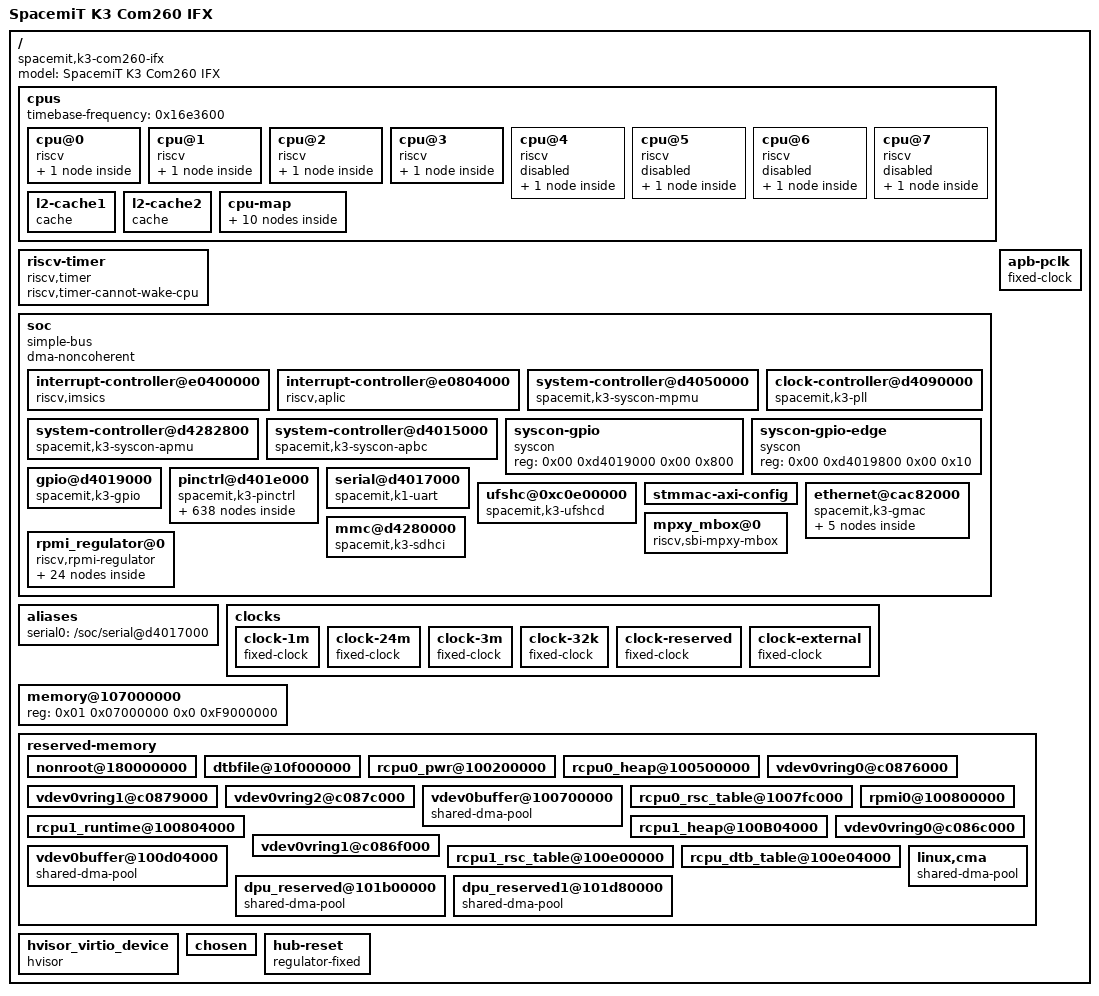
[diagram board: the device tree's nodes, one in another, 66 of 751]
/dts-v1/;

/ {
	#address-cells = <0x02>;
	#size-cells = <0x02>;
	model = "SpacemiT K3 Com260 IFX";
	compatible = "spacemit,k3-com260-ifx";

	cpus {
		#address-cells = <0x01>;
		#size-cells = <0x00>;
		timebase-frequency = <0x16e3600>;

		cpu@0 {
			device_type = "cpu";
			reg = <0x00>;
			model = "Spacemit(R) X100";
			status = "okay";
			compatible = "riscv";
			riscv,isa = "rv64imafdcv";
			riscv,isa-base = "rv64i";
			riscv,isa-extensions = "i\0m\0a\0f\0d\0c\0v\0smaia\0smstateen\0ssaia\0sscofpmf\0sstc\0svpbmt\0svinval\0svnapot\0zawrs\0zba\0zbb\0zbc\0zbs\0zcb\0zca\0zcmop\0zfa\0zfh\0zfhmin\0zkt\0zicbom\0zicbop\0zicboz\0zicntr\0zicond\0zicsr\0zifencei\0zihintpause\0zihintntl\0zihpm\0zimop\0zvbb\0zvbc\0zvfh\0zvfhmin\0zvkb\0zvkg\0zvkn\0zvknc\0zvkned\0zvkng\0zvknha\0zvknhb\0zvks\0zvksc\0zvksed\0zvksh\0zvksg\0zvkt\0zcd";
			riscv,cbom-block-size = <0x40>;
			riscv,cboz-block-size = <0x40>;
			riscv,cbop-block-size = <0x40>;
			i-cache-block-size = <0x40>;
			i-cache-size = <0x10000>;
			i-cache-sets = <0x100>;
			d-cache-block-size = <0x40>;
			d-cache-size = <0x10000>;
			d-cache-sets = <0x100>;
			next-level-cache = <0x01>;
			// cpu-idle-states = <0x02 0x03>;
			mmu-type = "riscv,sv39";
			#cooling-cells = <0x02>;
			clst-supply = <0x04>;
			clocks = <0x05 0x04 0x05 0x05>;
			clock-names = "cls0\0cls1";
			// operating-points-v2 = <0x06>;
			phandle = <0x0b>;

			interrupt-controller {
				#interrupt-cells = <0x01>;
				compatible = "riscv,cpu-intc";
				interrupt-controller;
				phandle = <0x69>;
			};
		};

		cpu@1 {
			device_type = "cpu";
			reg = <0x01>;
			model = "Spacemit(R) X100";
			status = "okay";
			compatible = "riscv";
			riscv,isa = "rv64imafdcv";
			riscv,isa-base = "rv64i";
			riscv,isa-extensions = "i\0m\0a\0f\0d\0c\0v\0smaia\0smstateen\0ssaia\0sscofpmf\0sstc\0svpbmt\0svinval\0svnapot\0zawrs\0zba\0zbb\0zbc\0zbs\0zcb\0zca\0zcmop\0zfa\0zfh\0zfhmin\0zkt\0zicbom\0zicbop\0zicboz\0zicntr\0zicond\0zicsr\0zifencei\0zihintpause\0zihintntl\0zihpm\0zimop\0zvbb\0zvbc\0zvfh\0zvfhmin\0zvkb\0zvkg\0zvkn\0zvknc\0zvkned\0zvkng\0zvknha\0zvknhb\0zvks\0zvksc\0zvksed\0zvksh\0zvksg\0zvkt\0zcd";
			riscv,cbom-block-size = <0x40>;
			riscv,cboz-block-size = <0x40>;
			riscv,cbop-block-size = <0x40>;
			i-cache-block-size = <0x40>;
			i-cache-size = <0x10000>;
			i-cache-sets = <0x100>;
			d-cache-block-size = <0x40>;
			d-cache-size = <0x10000>;
			d-cache-sets = <0x100>;
			next-level-cache = <0x01>;
			// cpu-idle-states = <0x02 0x03>;
			mmu-type = "riscv,sv39";
			#cooling-cells = <0x02>;
			clst-supply = <0x04>;
			clocks = <0x05 0x04 0x05 0x05>;
			clock-names = "cls0\0cls1";
			// operating-points-v2 = <0x06>;
			phandle = <0x0c>;

			interrupt-controller {
				#interrupt-cells = <0x01>;
				compatible = "riscv,cpu-intc";
				interrupt-controller;
				phandle = <0x6a>;
			};
		};

		cpu@2 {
			device_type = "cpu";
			reg = <0x02>;
			model = "Spacemit(R) X100";
			status = "okay";
			compatible = "riscv";
			riscv,isa = "rv64imafdcv";
			riscv,isa-base = "rv64i";
			riscv,isa-extensions = "i\0m\0a\0f\0d\0c\0v\0smaia\0smstateen\0ssaia\0sscofpmf\0sstc\0svpbmt\0svinval\0svnapot\0zawrs\0zba\0zbb\0zbc\0zbs\0zcb\0zca\0zcmop\0zfa\0zfh\0zfhmin\0zkt\0zicbom\0zicbop\0zicboz\0zicntr\0zicond\0zicsr\0zifencei\0zihintpause\0zihintntl\0zihpm\0zimop\0zvbb\0zvbc\0zvfh\0zvfhmin\0zvkb\0zvkg\0zvkn\0zvknc\0zvkned\0zvkng\0zvknha\0zvknhb\0zvks\0zvksc\0zvksed\0zvksh\0zvksg\0zvkt\0zcd";
			riscv,cbom-block-size = <0x40>;
			riscv,cboz-block-size = <0x40>;
			riscv,cbop-block-size = <0x40>;
			i-cache-block-size = <0x40>;
			i-cache-size = <0x10000>;
			i-cache-sets = <0x100>;
			d-cache-block-size = <0x40>;
			d-cache-size = <0x10000>;
			d-cache-sets = <0x100>;
			next-level-cache = <0x01>;
			// cpu-idle-states = <0x02 0x03>;
			mmu-type = "riscv,sv39";
			#cooling-cells = <0x02>;
			clst-supply = <0x04>;
			clocks = <0x05 0x04 0x05 0x05>;
			clock-names = "cls0\0cls1";
			// operating-points-v2 = <0x06>;
			phandle = <0x0d>;

			interrupt-controller {
				#interrupt-cells = <0x01>;
				compatible = "riscv,cpu-intc";
				interrupt-controller;
				phandle = <0x6b>;
			};
		};

		cpu@3 {
			device_type = "cpu";
			reg = <0x03>;
			model = "Spacemit(R) X100";
			status = "okay";
			compatible = "riscv";
			riscv,isa = "rv64imafdcv";
			riscv,isa-base = "rv64i";
			riscv,isa-extensions = "i\0m\0a\0f\0d\0c\0v\0smaia\0smstateen\0ssaia\0sscofpmf\0sstc\0svpbmt\0svinval\0svnapot\0zawrs\0zba\0zbb\0zbc\0zbs\0zcb\0zca\0zcmop\0zfa\0zfh\0zfhmin\0zkt\0zicbom\0zicbop\0zicboz\0zicntr\0zicond\0zicsr\0zifencei\0zihintpause\0zihintntl\0zihpm\0zimop\0zvbb\0zvbc\0zvfh\0zvfhmin\0zvkb\0zvkg\0zvkn\0zvknc\0zvkned\0zvkng\0zvknha\0zvknhb\0zvks\0zvksc\0zvksed\0zvksh\0zvksg\0zvkt\0zcd";
			riscv,cbom-block-size = <0x40>;
			riscv,cboz-block-size = <0x40>;
			riscv,cbop-block-size = <0x40>;
			i-cache-block-size = <0x40>;
			i-cache-size = <0x10000>;
			i-cache-sets = <0x100>;
			d-cache-block-size = <0x40>;
			d-cache-size = <0x10000>;
			d-cache-sets = <0x100>;
			next-level-cache = <0x01>;
			// cpu-idle-states = <0x02 0x03>;
			mmu-type = "riscv,sv39";
			#cooling-cells = <0x02>;
			clst-supply = <0x04>;
			clocks = <0x05 0x04 0x05 0x05>;
			clock-names = "cls0\0cls1";
			// operating-points-v2 = <0x06>;
			phandle = <0x0e>;

			interrupt-controller {
				#interrupt-cells = <0x01>;
				compatible = "riscv,cpu-intc";
				interrupt-controller;
				phandle = <0x6c>;
			};
		};

		cpu@4 {
			device_type = "cpu";
			reg = <0x04>;
			model = "Spacemit(R) X100";
			status = "disabled";
			compatible = "riscv";
			riscv,isa = "rv64imafdcv";
			riscv,isa-base = "rv64i";
			riscv,isa-extensions = "i\0m\0a\0f\0d\0c\0v\0smaia\0smstateen\0ssaia\0sscofpmf\0sstc\0svpbmt\0svinval\0svnapot\0zawrs\0zba\0zbb\0zbc\0zbs\0zcb\0zca\0zcmop\0zfa\0zfh\0zfhmin\0zkt\0zicbom\0zicbop\0zicboz\0zicntr\0zicond\0zicsr\0zifencei\0zihintpause\0zihintntl\0zihpm\0zimop\0zvbb\0zvbc\0zvfh\0zvfhmin\0zvkb\0zvkg\0zvkn\0zvknc\0zvkned\0zvkng\0zvknha\0zvknhb\0zvks\0zvksc\0zvksed\0zvksh\0zvksg\0zvkt\0zcd";
			riscv,cbom-block-size = <0x40>;
			riscv,cboz-block-size = <0x40>;
			riscv,cbop-block-size = <0x40>;
			i-cache-block-size = <0x40>;
			i-cache-size = <0x10000>;
			i-cache-sets = <0x100>;
			d-cache-block-size = <0x40>;
			d-cache-size = <0x10000>;
			d-cache-sets = <0x100>;
			next-level-cache = <0x07>;
			// cpu-idle-states = <0x02 0x03>;
			mmu-type = "riscv,sv39";
			#cooling-cells = <0x02>;
			clst-supply = <0x04>;
			clocks = <0x05 0x04 0x05 0x05>;
			clock-names = "cls0\0cls1";
			// operating-points-v2 = <0x06>;
			phandle = <0x0f>;

			interrupt-controller {
				#interrupt-cells = <0x01>;
				compatible = "riscv,cpu-intc";
				interrupt-controller;
				phandle = <0x6d>;
			};
		};

		cpu@5 {
			device_type = "cpu";
			reg = <0x05>;
			model = "Spacemit(R) X100";
			status = "disabled";
			compatible = "riscv";
			riscv,isa = "rv64imafdcv";
			riscv,isa-base = "rv64i";
			riscv,isa-extensions = "i\0m\0a\0f\0d\0c\0v\0smaia\0smstateen\0ssaia\0sscofpmf\0sstc\0svpbmt\0svinval\0svnapot\0zawrs\0zba\0zbb\0zbc\0zbs\0zcb\0zca\0zcmop\0zfa\0zfh\0zfhmin\0zkt\0zicbom\0zicbop\0zicboz\0zicntr\0zicond\0zicsr\0zifencei\0zihintpause\0zihintntl\0zihpm\0zimop\0zvbb\0zvbc\0zvfh\0zvfhmin\0zvkb\0zvkg\0zvkn\0zvknc\0zvkned\0zvkng\0zvknha\0zvknhb\0zvks\0zvksc\0zvksed\0zvksh\0zvksg\0zvkt\0zcd";
			riscv,cbom-block-size = <0x40>;
			riscv,cboz-block-size = <0x40>;
			riscv,cbop-block-size = <0x40>;
			i-cache-block-size = <0x40>;
			i-cache-size = <0x10000>;
			i-cache-sets = <0x100>;
			d-cache-block-size = <0x40>;
			d-cache-size = <0x10000>;
			d-cache-sets = <0x100>;
			next-level-cache = <0x07>;
			// cpu-idle-states = <0x02 0x03>;
			mmu-type = "riscv,sv39";
			#cooling-cells = <0x02>;
			clst-supply = <0x04>;
			clocks = <0x05 0x04 0x05 0x05>;
			clock-names = "cls0\0cls1";
			// operating-points-v2 = <0x06>;
			phandle = <0x10>;

			interrupt-controller {
				#interrupt-cells = <0x01>;
				compatible = "riscv,cpu-intc";
				interrupt-controller;
				phandle = <0x6e>;
			};
		};

		cpu@6 {
			device_type = "cpu";
			reg = <0x06>;
			model = "Spacemit(R) X100";
			status = "disabled";
			compatible = "riscv";
			riscv,isa = "rv64imafdcv";
			riscv,isa-base = "rv64i";
			riscv,isa-extensions = "i\0m\0a\0f\0d\0c\0v\0smaia\0smstateen\0ssaia\0sscofpmf\0sstc\0svpbmt\0svinval\0svnapot\0zawrs\0zba\0zbb\0zbc\0zbs\0zcb\0zca\0zcmop\0zfa\0zfh\0zfhmin\0zkt\0zicbom\0zicbop\0zicboz\0zicntr\0zicond\0zicsr\0zifencei\0zihintpause\0zihintntl\0zihpm\0zimop\0zvbb\0zvbc\0zvfh\0zvfhmin\0zvkb\0zvkg\0zvkn\0zvknc\0zvkned\0zvkng\0zvknha\0zvknhb\0zvks\0zvksc\0zvksed\0zvksh\0zvksg\0zvkt\0zcd";
			riscv,cbom-block-size = <0x40>;
			riscv,cboz-block-size = <0x40>;
			riscv,cbop-block-size = <0x40>;
			i-cache-block-size = <0x40>;
			i-cache-size = <0x10000>;
			i-cache-sets = <0x100>;
			d-cache-block-size = <0x40>;
			d-cache-size = <0x10000>;
			d-cache-sets = <0x100>;
			next-level-cache = <0x07>;
			// cpu-idle-states = <0x02 0x03>;
			mmu-type = "riscv,sv39";
			#cooling-cells = <0x02>;
			clst-supply = <0x04>;
			clocks = <0x05 0x04 0x05 0x05>;
			clock-names = "cls0\0cls1";
			// operating-points-v2 = <0x06>;
			phandle = <0x11>;

			interrupt-controller {
				#interrupt-cells = <0x01>;
				compatible = "riscv,cpu-intc";
				interrupt-controller;
				phandle = <0x6f>;
			};
		};

		cpu@7 {
			device_type = "cpu";
			reg = <0x07>;
			model = "Spacemit(R) X100";
			status = "disabled";
			compatible = "riscv";
			riscv,isa = "rv64imafdcv";
			riscv,isa-base = "rv64i";
			riscv,isa-extensions = "i\0m\0a\0f\0d\0c\0v\0smaia\0smstateen\0ssaia\0sscofpmf\0sstc\0svpbmt\0svinval\0svnapot\0zawrs\0zba\0zbb\0zbc\0zbs\0zcb\0zca\0zcmop\0zfa\0zfh\0zfhmin\0zkt\0zicbom\0zicbop\0zicboz\0zicntr\0zicond\0zicsr\0zifencei\0zihintpause\0zihintntl\0zihpm\0zimop\0zvbb\0zvbc\0zvfh\0zvfhmin\0zvkb\0zvkg\0zvkn\0zvknc\0zvkned\0zvkng\0zvknha\0zvknhb\0zvks\0zvksc\0zvksed\0zvksh\0zvksg\0zvkt\0zcd";
			riscv,cbom-block-size = <0x40>;
			riscv,cboz-block-size = <0x40>;
			riscv,cbop-block-size = <0x40>;
			i-cache-block-size = <0x40>;
			i-cache-size = <0x10000>;
			i-cache-sets = <0x100>;
			d-cache-block-size = <0x40>;
			d-cache-size = <0x10000>;
			d-cache-sets = <0x100>;
			next-level-cache = <0x07>;
			// cpu-idle-states = <0x02 0x03>;
			mmu-type = "riscv,sv39";
			#cooling-cells = <0x02>;
			clst-supply = <0x04>;
			clocks = <0x05 0x04 0x05 0x05>;
			clock-names = "cls0\0cls1";
			// operating-points-v2 = <0x06>;
			phandle = <0x12>;

			interrupt-controller {
				#interrupt-cells = <0x01>;
				compatible = "riscv,cpu-intc";
				interrupt-controller;
				phandle = <0x70>;
			};
		};

		l2-cache1 {
			compatible = "cache";
			cache-block-size = <0x40>;
			cache-level = <0x02>;
			cache-size = <0x400000>;
			cache-sets = <0x1000>;
			cache-unified;
			phandle = <0x01>;
		};

		l2-cache2 {
			compatible = "cache";
			cache-block-size = <0x40>;
			cache-level = <0x02>;
			cache-size = <0x400000>;
			cache-sets = <0x1000>;
			cache-unified;
			phandle = <0x07>;
		};

		cpu-map {
			cluster0 {
				core0 {
					cpu = <0x0b>;
				};

				core1 {
					cpu = <0x0c>;
				};

				core2 {
					cpu = <0x0d>;
				};

				core3 {
					cpu = <0x0e>;
				};
			};

			cluster1 {

				core0 {
					cpu = <0x0f>;
				};

				core1 {
					cpu = <0x10>;
				};

				core2 {
					cpu = <0x11>;
				};

				core3 {
					cpu = <0x12>;
				};
			};
		};
	};

	riscv-timer {
		compatible = "riscv,timer";
		riscv,timer-cannot-wake-cpu;
	};

	soc {
		#address-cells = <0x02>;
		#size-cells = <0x02>;
		compatible = "simple-bus";
		dma-noncoherent;
		ranges;

		interrupt-controller@e0400000 {
			compatible = "riscv,imsics";
			interrupts-extended = <0x69 0x09 0x6a 0x09 0x6b 0x09 0x6c 0x09>;
			reg = <0x00 0xe0400000 0x00 0x4000>;
			interrupt-controller;
			#interrupt-cells = <0x00>;
			#msi-cells = <0x00>;
			msi-controller;
			riscv,num-ids = <0x1ff>;
			riscv,num-guest-ids = <0x1ff>;
			riscv,hart-index-bits = <0x03>;
			riscv,guest-index-bits = <0>;
			status = "okay";
			phandle = <0x79>;
		};

		interrupt-controller@e0804000 {
			compatible = "riscv,aplic";
			reg = <0x00 0xe0804000 0x00 0x4000>;
			msi-parent = <0x79>;
			#interrupt-cells = <0x02>;
			interrupt-controller;
			riscv,num-sources = <0x200>;
			status = "okay";
			phandle = <0x82>;
		};

		system-controller@d4050000 {
			compatible = "spacemit,k3-syscon-mpmu";
			reg = <0x00 0xd4050000 0x00 0x10000>;
			clocks = <0x7a 0x7b 0x7c 0x7d 0x7e 0x7f>;
			clock-names = "osc_32k\0vctcxo_1m\0vctcxo_3m\0vctcxo_24m\0reserved_clk\0external_clk";
			#clock-cells = <0x01>;
			#reset-cells = <0x01>;
			phandle = <0x80>;
		};

		clock-controller@d4090000 {
			compatible = "spacemit,k3-pll";
			reg = <0x00 0xd4090000 0x00 0x10000>;
			clocks = <0x7d>;
			spacemit,mpmu = <0x80>;
			#clock-cells = <0x01>;
			phandle = <0x1b>;
		};

		system-controller@d4282800 {
			compatible = "spacemit,k3-syscon-apmu";
			reg = <0x00 0xd4282800 0x00 0x400>;
			clocks = <0x7a 0x7b 0x7c 0x7d 0x7e 0x7f>;
			clock-names = "osc_32k\0vctcxo_1m\0vctcxo_3m\0vctcxo_24m\0reserved_clk\0external_clk";
			#clock-cells = <0x01>;
			#power-domain-cells = <0x01>;
			#reset-cells = <0x01>;
			phandle = <0x05>;
		};

		system-controller@d4015000 {
			compatible = "spacemit,k3-syscon-apbc";
			reg = <0x00 0xd4015000 0x00 0x1000>;
			clocks = <0x7a 0x7b 0x7c 0x7d 0x7e 0x7f>;
			clock-names = "osc_32k\0vctcxo_1m\0vctcxo_3m\0vctcxo_24m\0reserved_clk\0external_clk";
			#clock-cells = <0x01>;
			#reset-cells = <0x01>;
			phandle = <0x81>;
		};

		syscon-gpio {
			compatible = "syscon";
			reg = <0x00 0xd4019000 0x00 0x800>;
			phandle = <0x83>;
		};

		syscon-gpio-edge {
			compatible = "syscon";
			reg = <0x00 0xd4019800 0x00 0x10>;
			phandle = <0x84>;
		};

		gpio@d4019000 {
			compatible = "spacemit,k3-gpio";
			reg = <0x00 0xd4019000 0x00 0x100>;
			clocks = <0x81 0x14 0x81 0x15>;
			clock-names = "core\0bus";
			gpio-controller;
			#gpio-cells = <0x03>;
			interrupts = <0x3a 0x04>;
			interrupt-parent = <0x82>;
			interrupt-controller;
			#interrupt-cells = <0x03>;
			syscon-gpio-regs = <0x83>;
			syscon-gpio-edge = <0x84>;
			gpio-ranges = <0x85 0x00 0x00 0x00 0x20 0x85 0x01 0x00 0x20 0x20 0x85 0x02 0x00 0x40 0x20 0x85 0x03 0x00 0x60 0x20>;
			phandle = <0x8b>;
		};

		pinctrl@d401e000 {
			compatible = "spacemit,k3-pinctrl";
			reg = <0x00 0xd401e000 0x00 0x400 0x00 0xd401e800 0x00 0x34>;
			clocks = <0x81 0x67 0x81 0x68>;
			clock-names = "func\0bus";
			interrupt-controller;
			#interrupt-cells = <0x02>;
			interrupts = <0x3c 0x04>;
			interrupt-parent = <0x82>;
			spacemit,gpio-edge = <0x84>;
			spacemit,apbc = <0x81 0x50>;
			spacemit,apmu = <0x05>;
			phandle = <0x85>;

			uart0-0-cfg {
				phandle = <0x86>;

				uart0-0-pins {
					pinmux = <0x950002 0x960002>;
					bias-pull-up;
					drive-strength = <0x19>;
				};
			};

			uart0-1-cfg {

				uart0-0-pins {
					pinmux = <0x840002 0x850002>;
					bias-pull-up;
					drive-strength = <0x19>;
				};
			};

			uart0-2-cfg {

				uart0-0-pins {
					pinmux = <0x910005 0x920005>;
					bias-pull-up;
					drive-strength = <0x19>;
				};
			};

			uart0-3-cfg {

				uart0-0-pins {
					pinmux = <0x2a0002 0x2b0002>;
					bias-pull-up;
					drive-strength = <0x19>;
				};
			};

			uart0-4-cfg {

				uart0-0-pins {
					pinmux = <0x5d0003 0x5e0003>;
					bias-pull-up;
					drive-strength = <0x19>;
				};
			};

			uart1-0-cfg {

				uart1-0-pins {
					pinmux = <0x5f0002 0x600002 0x610002 0x620002>;
					bias-pull-up;
					drive-strength = <0x19>;
				};
			};

			uart1-1-cfg {

				uart1-0-pins {
					pinmux = <0x760001 0x770001 0x780001 0x790001>;
					bias-pull-up;
					drive-strength = <0x19>;
				};
			};

			uart2-0-cfg {

				uart2-0-pins {
					pinmux = <0x860002 0x870002 0x880002 0x890002>;
					bias-pull-up;
					drive-strength = <0x19>;
				};
			};

			uart2-1-cfg {

				uart2-0-pins {
					pinmux = <0x610001 0x620001>;
					bias-pull-up;
					drive-strength = <0x19>;
				};
			};

			uart3-0-cfg {

				uart3-0-pins {
					pinmux = <0x1a0002 0x1b0002 0x1c0002 0x1d0002>;
					bias-pull-up;
					drive-strength = <0x19>;
				};
			};

			uart3-1-cfg {

				uart3-0-pins {
					pinmux = <0x350002 0x360002 0x370002 0x380002>;
					bias-pull-up;
					drive-strength = <0x19>;
				};
			};

			uart4-0-cfg {

				uart4-0-pins {
					pinmux = <0x560003 0x570003 0x5a0003 0x5b0003>;
					bias-pull-up;
					drive-strength = <0x19>;
				};
			};

			uart4-1-cfg {

				uart4-0-pins {
					pinmux = <0x630003 0x640003 0x650003 0x660003>;
					bias-pull-up;
					drive-strength = <0x19>;
				};
			};

			uart5-0-cfg {

				uart5-0-pins {
					pinmux = <0x910004 0x920004>;
					bias-pull-up;
					drive-strength = <0x19>;
				};
			};

			uart5-1-cfg {

				uart5-0-pins {
					pinmux = <0x150002 0x160002 0x170002 0x180002>;
					bias-pull-up;
					drive-strength = <0x19>;
				};
			};

			uart5-2-cfg {

				uart5-0-pins {
					pinmux = <0x520004 0x530004>;
					bias-pull-up;
					drive-strength = <0x19>;
				};
			};

			uart6-0-cfg {

				uart6-0-pins {
					pinmux = <0x300002 0x310002 0x320002 0x330002>;
					bias-pull-up;
					drive-strength = <0x19>;
				};
			};

			uart6-1-cfg {

				uart6-0-pins {
					pinmux = <0x7a0003 0x7b0003>;
					bias-pull-up;
					drive-strength = <0x19>;
				};
			};

			uart7-0-cfg {

				uart7-0-pins {
					pinmux = <0xb0002 0xc0002 0xd0002 0xe0002>;
					bias-pull-up;
					drive-strength = <0x19>;
				};
			};

			uart7-1-cfg {

				uart7-0-pins {
					pinmux = <0x170005 0x180005 0x190005 0x1a0005>;
					bias-pull-up;
					drive-strength = <0x19>;
				};
			};

			uart8-0-cfg {

				uart8-0-pins {
					pinmux = <0xb0005 0xc0005>;
					bias-pull-up;
					drive-strength = <0x19>;
				};
			};

			uart8-1-cfg {

				uart8-0-pins {
					pinmux = <0x4c0003 0x4d0003 0x4e0003 0x4f0003>;
					bias-pull-up;
					drive-strength = <0x19>;
				};
			};

			uart9-0-cfg {

				uart9-0-pins {
					pinmux = <0x930004 0x940004>;
					bias-pull-up;
					drive-strength = <0x19>;
				};
			};

			uart9-1-cfg {

				uart9-0-pins {
					pinmux = <0x520003 0x530003 0x540003 0x550003>;
					bias-pull-up;
					drive-strength = <0x19>;
				};
			};

			uart10-0-cfg {

				uart10-0-pins {
					pinmux = <0x1f0002 0x200002 0x210002 0x220002>;
					bias-pull-up;
					drive-strength = <0x19>;
				};
			};

			uart10-1-cfg {

				uart10-0-pins {
					pinmux = <0x2c0002 0x2d0002 0x2e0002 0x2f0002>;
					bias-pull-up;
					drive-strength = <0x19>;
				};
			};

			ruart0-0-cfg {

				ruart0-0-pins {
					pinmux = <0x840004 0x850004>;
					bias-pull-up;
					drive-strength = <0x19>;
				};
			};

			ruart0-1-cfg {

				ruart0-0-pins {
					pinmux = <0x910006 0x920006>;
					bias-pull-up;
					drive-strength = <0x19>;
				};
			};

			ruart0-2-cfg {

				ruart0-0-pins {
					pinmux = <0x6d0003 0x6e0003>;
					bias-pull-up;
					drive-strength = <0x19>;
				};
			};

			ruart0-3-cfg {

				ruart0-0-pins {
					pinmux = <0x7a0004 0x7b0004>;
					bias-pull-up;
					drive-strength = <0x19>;
				};
			};

			ruart1_0-cfg {

				ruart1-0-pins {
					pinmux = <0x8a0002 0x8b0002 0x8c0002 0x8d0002>;
					bias-pull-up;
					drive-strength = <0x19>;
				};
			};

			ruart1-1-cfg {

				ruart1-0-pins {
					pinmux = <0x110005 0x120005 0x130005 0x140005>;
					bias-pull-up;
					drive-strength = <0x19>;
				};
			};

			ruart2-0-cfg {

				ruart2-0-pins {
					pinmux = <0x390002 0x3a0002>;
					bias-pull-up;
					drive-strength = <0x19>;
				};
			};

			ruart3-0-cfg {

				ruart3-0-pins {
					pinmux = <0x370004 0x380004>;
					bias-pull-up;
					drive-strength = <0x19>;
				};
			};

			ruart3-1-cfg {

				ruart3-0-pins {
					pinmux = <0x580003 0x590003>;
					bias-pull-up;
					drive-strength = <0x19>;
				};
			};

			ruart4-0-cfg {

				ruart4-0-pins {
					pinmux = <0x150005 0x160005>;
					bias-pull-up;
					drive-strength = <0x19>;
				};
			};

			ruart4-1-cfg {

				ruart4-0-pins {
					pinmux = <0x500003 0x510003>;
					bias-pull-up;
					drive-strength = <0x19>;
				};
			};

			ruart5-0-cfg {

				ruart5-0-pins {
					pinmux = <0x3b0002 0x3c0002>;
					bias-pull-up;
					drive-strength = <0x19>;
				};
			};

			i2c0-0-cfg {
				phandle = <0x89>;

				i2c0-0-pins {
					pinmux = <0x06 0x10006>;
					bias-pull-up;
					drive-strength = <0x19>;
					power-source = <0xce4>;
				};
			};

			i2c0-1-cfg {

				i2c0-0-pins {
					pinmux = <0x2a0005 0x2b0005>;
					bias-pull-up;
					drive-strength = <0x19>;
				};
			};

			i2c0-2-cfg {

				i2c0-0-pins {
					pinmux = <0x300005 0x310005>;
					bias-pull-up;
					drive-strength = <0x19>;
				};
			};

			i2c0-3-cfg {

				i2c0-0-pins {
					pinmux = <0x4c0006 0x4d0006>;
					bias-pull-up;
					drive-strength = <0x19>;
				};
			};

			i2c0-4-cfg {

				i2c0-0-pins {
					pinmux = <0x730004 0x740004>;
					bias-pull-up;
					drive-strength = <0x19>;
				};
			};

			i2c1-0-cfg {

				i2c1-0-pins {
					pinmux = <0x20006 0x30006>;
					bias-pull-up;
					drive-strength = <0x19>;
				};
			};

			i2c1-1-cfg {
				phandle = <0x8e>;

				i2c1-0-pins {
					pinmux = <0x360005 0x370005>;
					bias-pull-up;
					drive-strength = <0x19>;
					power-source = <0x708>;
				};
			};

			i2c1-2-cfg {

				i2c1-0-pins {
					pinmux = <0x4e0006 0x4f0006>;
					bias-pull-up;
					drive-strength = <0x19>;
				};
			};

			i2c1-3-cfg {

				i2c1-0-pins {
					pinmux = <0x660006 0x670006>;
					bias-pull-up;
					drive-strength = <0x19>;
				};
			};

			i2c2-0-cfg {

				i2c2-0-pins {
					pinmux = <0x50006 0x60006>;
					bias-pull-up;
					drive-strength = <0x19>;
				};
			};

			i2c2-1-cfg {
				phandle = <0x8f>;

				i2c2-0-pins {
					pinmux = <0x2e0005 0x2f0005>;
					bias-pull-up;
					drive-strength = <0x19>;
					power-source = <0x708>;
				};
			};

			i2c2-2-cfg {

				i2c2-0-pins {
					pinmux = <0x500006 0x510006>;
					bias-pull-up;
					drive-strength = <0x19>;
				};
			};

			i2c2-3-cfg {

				i2c2-0-pins {
					pinmux = <0x780002 0x790002>;
					bias-pull-up;
					drive-strength = <0x19>;
				};
			};

			i2c3-0-cfg {

				i2c3-0-pins {
					pinmux = <0x8e0005 0x8f0005>;
					bias-pull-up;
					drive-strength = <0x19>;
				};
			};

			i2c3-1-cfg {

				i2c3-0-pins {
					pinmux = <0x240004 0x250004>;
					bias-pull-up;
					drive-strength = <0x19>;
				};
			};

			i2c3-2-cfg {
				phandle = <0x90>;

				i2c3-0-pins {
					pinmux = <0x520006 0x530006>;
					bias-pull-up;
					drive-strength = <0x19>;
					power-source = <0xce4>;
				};
			};

			i2c3-3-cfg {

				i2c3-0-pins {
					pinmux = <0x690004 0x6a0004>;
					bias-pull-up;
					drive-strength = <0x19>;
				};
			};

			i2c4-0-cfg {

				i2c4-0-pins {
					pinmux = <0x880006 0x890006>;
					bias-pull-up;
					drive-strength = <0x19>;
				};
			};

			i2c4-1-cfg {

				i2c4-0-pins {
					pinmux = <0xb0006 0xc0006>;
					bias-pull-up;
					drive-strength = <0x19>;
				};
			};

			i2c4-2-cfg {

				i2c4-0-pins {
					pinmux = <0x320005 0x330005>;
					bias-pull-up;
					drive-strength = <0x19>;
				};
			};

			i2c4-3-cfg {

				i2c4-0-pins {
					pinmux = <0x6f0004 0x700004>;
					bias-pull-up;
					drive-strength = <0x19>;
				};
			};

			touchpad-int-cfg {

				touchpad-int-pins {
					pinmux = <0x1a0000>;
					bias-pull-up;
					power-source = <0xce4>;
				};
			};

			i2c5-0-cfg {

				i2c5-0-pins {
					pinmux = <0x190006 0x1a0006>;
					bias-pull-up;
					drive-strength = <0x19>;
				};
			};

			i2c5-1-cfg {

				i2c5-0-pins {
					pinmux = <0x3f0005 0x400005>;
					bias-pull-up;
					drive-strength = <0x19>;
				};
			};

			i2c5-2-cfg {
				phandle = <0x92>;

				i2c5-0-pins {
					pinmux = <0x5d0005 0x5e0005>;
					bias-pull-up;
					drive-strength = <0x19>;
					power-source = <0x708>;
				};
			};

			i2c5-3-cfg {

				i2c5-0-pins {
					pinmux = <0x7e0004 0x7f0004>;
					bias-pull-up;
					drive-strength = <0x19>;
				};
			};

			i2c6-0-cfg {

				i2c6-0-pins {
					pinmux = <0x970002 0x980002>;
					bias-pull-up;
					drive-strength = <0x19>;
				};
			};

			i2c6-1-cfg {
				phandle = <0x96>;

				i2c6-0-pins {
					pinmux = <0x70006 0x80006>;
					bias-pull-up;
					drive-strength = <0x12>;
					power-source = <0xce4>;
				};
			};

			i2c6-2-cfg {

				i2c6-0-pins {
					pinmux = <0xe0006 0xf0006>;
					bias-pull-up;
					drive-strength = <0x12>;
				};
			};

			i2c6-3-cfg {

				i2c6-0-pins {
					pinmux = <0x3d0005 0x3e0005>;
					bias-pull-up;
					drive-strength = <0x19>;
				};
			};

			i2c8-cfg {

				i2c8-pins {
					pinmux = <0x800000 0x810000>;
					bias-pull-up;
					drive-strength = <0x19>;
				};
			};

			i2c8-cfg-rcpu {
				phandle = <0xa9>;

				i2c8-pins-rcpu {
					pinmux = <0x800001 0x810001>;
					bias-pull-up;
					drive-strength = <0x19>;
				};
			};

			ri2c0-0-cfg {

				ri2c0-0-pins {
					pinmux = <0x1b0006 0x1c0006>;
					bias-pull-up;
					drive-strength = <0x19>;
				};
			};

			ri2c0-1-cfg {

				ri2c0-0-pins {
					pinmux = <0x390005 0x3a0005>;
					bias-pull-up;
					drive-strength = <0x19>;
				};
			};

			ri2c0-2-cfg {

				ri2c0-0-pins {
					pinmux = <0x4a0006 0x4b0006>;
					bias-pull-up;
					drive-strength = <0x19>;
				};
			};

			ri2c0-3-cfg {

				ri2c0-0-pins {
					pinmux = <0x730006 0x740006>;
					bias-pull-up;
					drive-strength = <0x19>;
				};
			};

			ri2c1-0-cfg {

				ri2c1-0-pins {
					pinmux = <0x210006 0x220006>;
					bias-pull-up;
					drive-strength = <0x19>;
				};
			};

			ri2c1-1-cfg {

				ri2c1-0-pins {
					pinmux = <0x270004 0x280004>;
					bias-pull-up;
					drive-strength = <0x19>;
				};
			};

			ri2c1-2-cfg {

				ri2c1-0-pins {
					pinmux = <0x3b0005 0x3c0005>;
					bias-pull-up;
					drive-strength = <0x19>;
				};
			};

			ri2c1-3-cfg {

				ri2c1-0-pins {
					pinmux = <0x690003 0x6a0003>;
					bias-pull-up;
					drive-strength = <0x19>;
				};
			};

			pwm0-0-cfg {

				pwm0-0-pins {
					pinmux = <0x2b0006>;
					bias-pull-up;
					drive-strength = <0x19>;
				};
			};

			pwm0-1-cfg {

				pwm0-0-pins {
					pinmux = <0x2a0006>;
					bias-pull-up;
					drive-strength = <0x19>;
				};
			};

			pwm1-0-cfg {

				pwm1-0-pins {
					pinmux = <0x10003>;
					bias-pull-up;
					drive-strength = <0x19>;
				};
			};

			pwm1-2-cfg {

				pwm1-0-pins {
					pinmux = <0x5f0006>;
					bias-pull-up;
					drive-strength = <0x19>;
				};
			};

			pwm2-0-cfg {

				pwm2-0-pins {
					pinmux = <0x20003>;
					bias-pull-up;
					drive-strength = <0x19>;
				};
			};

			pwm2-1-cfg {

				pwm2-0-pins {
					pinmux = <0x2c0006>;
					bias-pull-up;
					drive-strength = <0x19>;
				};
			};

			pwm2-2-cfg {

				pwm2-0-pins {
					pinmux = <0x600006>;
					bias-pull-up;
					drive-strength = <0x19>;
				};
			};

			pwm2-3-cfg {

				pwm2-0-pins {
					pinmux = <0x860004>;
					bias-pull-up;
					drive-strength = <0x19>;
				};
			};

			pwm3-0-cfg {

				pwm3-0-pins {
					pinmux = <0x30003>;
					bias-pull-up;
					drive-strength = <0x19>;
				};
			};

			pwm3-1-cfg {

				pwm3-0-pins {
					pinmux = <0x2d0006>;
					bias-pull-up;
					drive-strength = <0x19>;
				};
			};

			pwm3-2-cfg {

				pwm3-0-pins {
					pinmux = <0x610006>;
					bias-pull-up;
					drive-strength = <0x19>;
				};
			};

			pwm3-3-cfg {

				pwm3-0-pins {
					pinmux = <0x870004>;
					bias-pull-up;
					drive-strength = <0x19>;
				};
			};

			pwm4-0-cfg {

				pwm4-0-pins {
					pinmux = <0x40003>;
					bias-pull-up;
					drive-strength = <0x19>;
				};
			};

			pwm4-1-cfg {

				pwm4-0-pins {
					pinmux = <0x2e0006>;
					bias-pull-up;
					drive-strength = <0x19>;
				};
			};

			pwm4-2-cfg {

				pwm4-0-pins {
					pinmux = <0x880004>;
					bias-pull-up;
					drive-strength = <0x19>;
				};
			};

			pwm5-0-cfg {

				pwm5-0-pins {
					pinmux = <0x50003>;
					bias-pull-up;
					drive-strength = <0x19>;
				};
			};

			pwm5-1-cfg {

				pwm5-0-pins {
					pinmux = <0x2f0006>;
					bias-pull-up;
					drive-strength = <0x19>;
				};
			};

			pwm5-2-cfg {

				pwm5-0-pins {
					pinmux = <0x890004>;
					bias-pull-up;
					drive-strength = <0x19>;
				};
			};

			pwm6-0-cfg {

				pwm6-0-pins {
					pinmux = <0x60003>;
					bias-pull-up;
					drive-strength = <0x19>;
				};
			};

			pwm6-1-cfg {

				pwm6-0-pins {
					pinmux = <0x910003>;
					bias-pull-up;
					drive-strength = <0x19>;
				};
			};

			pwm6-2-cfg {

				pwm6-0-pins {
					pinmux = <0x300006>;
					bias-pull-up;
					drive-strength = <0x19>;
				};
			};

			pwm7-0-cfg {

				pwm7-0-pins {
					pinmux = <0x70003>;
					bias-pull-up;
					drive-strength = <0x19>;
				};
			};

			pwm7-1-cfg {

				pwm7-0-pins {
					pinmux = <0x920003>;
					bias-pull-up;
					drive-strength = <0x19>;
				};
			};

			pwm7-2-cfg {

				pwm7-0-pins {
					pinmux = <0x310006>;
					bias-pull-up;
					drive-strength = <0x19>;
				};
			};

			pwm8-0-cfg {

				pwm8-0-pins {
					pinmux = <0x80003>;
					bias-pull-up;
					drive-strength = <0x19>;
				};
			};

			pwm8-1-cfg {

				pwm8-0-pins {
					pinmux = <0x930003>;
					bias-pull-up;
					drive-strength = <0x19>;
				};
			};

			pwm8-2-cfg {

				pwm8-0-pins {
					pinmux = <0x320006>;
					bias-pull-up;
					drive-strength = <0x19>;
				};
			};

			pwm9-0-cfg {

				pwm9-0-pins {
					pinmux = <0x90003>;
					bias-pull-up;
					drive-strength = <0x19>;
				};
			};

			pwm9-1-cfg {

				pwm9-0-pins {
					pinmux = <0x940003>;
					bias-pull-up;
					drive-strength = <0x19>;
				};
			};

			pwm9-2-cfg {

				pwm9-0-pins {
					pinmux = <0x330006>;
					bias-pull-up;
					drive-strength = <0x19>;
				};
			};

			pwm10-0-cfg {

				pwm10-0-pins {
					pinmux = <0xa0003>;
					bias-pull-up;
					drive-strength = <0x19>;
				};
			};

			pwm10-1-cfg {

				pwm10-0-pins {
					pinmux = <0x340006>;
					bias-pull-up;
					drive-strength = <0x19>;
				};
			};

			pwm10-2-cfg {

				pwm10-0-pins {
					pinmux = <0x8d0004>;
					bias-pull-up;
					drive-strength = <0x19>;
				};
			};

			pwm11-0-cfg {

				pwm11-0-pins {
					pinmux = <0x350006>;
					bias-pull-up;
					drive-strength = <0x19>;
				};
			};

			pwm11-1-cfg {

				pwm11-0-pins {
					pinmux = <0x8c0004>;
					bias-pull-up;
					drive-strength = <0x19>;
				};
			};

			pwm12-0-cfg {

				pwm12-0-pins {
					pinmux = <0x360006>;
					bias-pull-up;
					drive-strength = <0x19>;
				};
			};

			pwm12-1-cfg {

				pwm12-0-pins {
					pinmux = <0x8b0004>;
					bias-pull-up;
					drive-strength = <0x19>;
				};
			};

			pwm13-0-cfg {

				pwm13-0-pins {
					pinmux = <0x370006>;
					bias-pull-up;
					drive-strength = <0x19>;
				};
			};

			pwm13-1-cfg {

				pwm13-0-pins {
					pinmux = <0x8a0004>;
					bias-pull-up;
					drive-strength = <0x19>;
				};
			};

			pwm13-2-cfg {

				pwm13-0-pins {
					pinmux = <0xd0003>;
					bias-pull-up;
					drive-strength = <0x19>;
				};
			};

			pwm14-0-cfg {

				pwm14-0-pins {
					pinmux = <0x380006>;
					bias-pull-up;
					drive-strength = <0x19>;
				};
			};

			pwm14-1-cfg {

				pwm14-0-pins {
					pinmux = <0x900004>;
					bias-pull-up;
					drive-strength = <0x19>;
				};
			};

			pwm14-2-cfg {

				pwm14-0-pins {
					pinmux = <0xe0003>;
					bias-pull-up;
					drive-strength = <0x19>;
				};
			};

			pwm15-0-cfg {

				pwm15-0-pins {
					pinmux = <0x390006>;
					bias-pull-up;
					drive-strength = <0x19>;
				};
			};

			pwm15-1-cfg {

				pwm15-0-pins {
					pinmux = <0x8e0004>;
					bias-pull-up;
					drive-strength = <0x19>;
				};
			};

			pwm15-2-cfg {

				pwm15-0-pins {
					pinmux = <0x150003>;
					bias-pull-up;
					drive-strength = <0x19>;
				};
			};

			pwm16-0-cfg {

				pwm16-0-pins {
					pinmux = <0x3a0006>;
					bias-pull-up;
					drive-strength = <0x19>;
				};
			};

			pwm16-1-cfg {

				pwm16-0-pins {
					pinmux = <0x8f0004>;
					bias-pull-up;
					drive-strength = <0x19>;
				};
			};

			pwm16-2-cfg {

				pwm16-0-pins {
					pinmux = <0x160003>;
					bias-pull-up;
					drive-strength = <0x19>;
				};
			};

			pwm17-0-cfg {

				pwm17-0-pins {
					pinmux = <0x170003>;
					bias-pull-up;
					drive-strength = <0x19>;
				};
			};

			pwm17-1-cfg {

				pwm17-0-pins {
					pinmux = <0x3b0006>;
					bias-pull-up;
					drive-strength = <0x19>;
				};
			};

			pwm17-2-cfg {

				pwm17-0-pins {
					pinmux = <0x690006>;
					bias-pull-up;
					drive-strength = <0x19>;
				};
			};

			pwm18-0-cfg {

				pwm18-0-pins {
					pinmux = <0x180003>;
					bias-pull-up;
					drive-strength = <0x19>;
				};
			};

			pwm18-1-cfg {

				pwm18-0-pins {
					pinmux = <0x3c0006>;
					bias-pull-up;
					drive-strength = <0x19>;
				};
			};

			pwm18-2-cfg {

				pwm18-0-pins {
					pinmux = <0x6a0006>;
					bias-pull-up;
					drive-strength = <0x19>;
				};
			};

			pwm19-0-cfg {

				pwm19-0-pins {
					pinmux = <0x190003>;
					bias-pull-up;
					drive-strength = <0x19>;
				};
			};

			pwm19-1-cfg {

				pwm19-0-pins {
					pinmux = <0x3d0006>;
					bias-pull-up;
					drive-strength = <0x19>;
				};
			};

			pwm19-2-cfg {

				pwm19-0-pins {
					pinmux = <0x6b0006>;
					bias-pull-up;
					drive-strength = <0x19>;
				};
			};

			rpwm0-0-cfg {

				rpwm0-0-pins {
					pinmux = <0xf0003>;
					bias-pull-up;
					drive-strength = <0x19>;
				};
			};

			rpwm0-1-cfg {

				rpwm0-0-pins {
					pinmux = <0x1b0003>;
					bias-pull-up;
					drive-strength = <0x19>;
				};
			};

			rpwm0-2-cfg {

				rpwm0-0-pins {
					pinmux = <0x400006>;
					bias-pull-up;
					drive-strength = <0x19>;
				};
			};

			rpwm1-0-cfg {

				rpwm1-0-pins {
					pinmux = <0x100003>;
					bias-pull-up;
					drive-strength = <0x19>;
				};
			};

			rpwm1-1-cfg {

				rpwm1-0-pins {
					pinmux = <0x1c0003>;
					bias-pull-up;
					drive-strength = <0x19>;
				};
			};

			rpwm1-2-cfg {

				rpwm1-0-pins {
					pinmux = <0x410006>;
					bias-pull-up;
					drive-strength = <0x19>;
				};
			};

			rpwm2-0-cfg {

				rpwm2-0-pins {
					pinmux = <0x110003>;
					bias-pull-up;
					drive-strength = <0x19>;
				};
			};

			rpwm2-1-cfg {

				rpwm2-0-pins {
					pinmux = <0x1d0003>;
					bias-pull-up;
					drive-strength = <0x19>;
				};
			};

			rpwm2-2-cfg {

				rpwm2-0-pins {
					pinmux = <0x420006>;
					bias-pull-up;
					drive-strength = <0x19>;
				};
			};

			rpwm3-0-cfg {

				rpwm3-0-pins {
					pinmux = <0x120003>;
					bias-pull-up;
					drive-strength = <0x19>;
				};
			};

			rpwm3-1-cfg {

				rpwm3-0-pins {
					pinmux = <0x1e0003>;
					bias-pull-up;
					drive-strength = <0x19>;
				};
			};

			rpwm3-2-cfg {

				rpwm3-0-pins {
					pinmux = <0x430006>;
					bias-pull-up;
					drive-strength = <0x19>;
				};
			};

			rpwm4-0-cfg {

				rpwm4-0-pins {
					pinmux = <0x130003>;
					bias-pull-up;
					drive-strength = <0x19>;
				};
			};

			rpwm4-1-cfg {

				rpwm4-0-pins {
					pinmux = <0x1f0003>;
					bias-pull-up;
					drive-strength = <0x19>;
				};
			};

			rpwm4-2-cfg {

				rpwm4-0-pins {
					pinmux = <0x5d0006>;
					bias-pull-up;
					drive-strength = <0x19>;
				};
			};

			rpwm5-0-cfg {

				rpwm5-0-pins {
					pinmux = <0x140003>;
					bias-pull-up;
					drive-strength = <0x19>;
				};
			};

			rpwm5-1-cfg {

				rpwm5-0-pins {
					pinmux = <0x200003>;
					bias-pull-up;
					drive-strength = <0x19>;
				};
			};

			rpwm5-2-cfg {

				rpwm5-0-pins {
					pinmux = <0x5c0005>;
					bias-pull-up;
					drive-strength = <0x19>;
				};
			};

			rpwm6-0-cfg {

				rpwm6-0-pins {
					pinmux = <0x210003>;
					bias-pull-up;
					drive-strength = <0x19>;
				};
			};

			rpwm6-1-cfg {

				rpwm6-0-pins {
					pinmux = <0x5e0006>;
					bias-pull-up;
					drive-strength = <0x19>;
				};
			};

			rpwm6-2-cfg {

				rpwm6-0-pins {
					pinmux = <0x6d0006>;
					bias-pull-up;
					drive-strength = <0x19>;
				};
			};

			rpwm7-0-cfg {

				rpwm7-0-pins {
					pinmux = <0x220003>;
					bias-pull-up;
					drive-strength = <0x19>;
				};
			};

			rpwm7-1-cfg {

				rpwm7-0-pins {
					pinmux = <0x6e0006>;
					bias-pull-up;
					drive-strength = <0x19>;
				};
			};

			rpwm8-0-cfg {

				rpwm8-0-pins {
					pinmux = <0x230003>;
					bias-pull-up;
					drive-strength = <0x19>;
				};
			};

			rpwm8-1-cfg {

				rpwm8-0-pins {
					pinmux = <0x6f0006>;
					bias-pull-up;
					drive-strength = <0x19>;
				};
			};

			rpwm9-0-cfg {

				rpwm9-0-pins {
					pinmux = <0x240003>;
					bias-pull-up;
					drive-strength = <0x19>;
				};
			};

			rpwm9-1-cfg {

				rpwm9-0-pins {
					pinmux = <0x700006>;
					bias-pull-up;
					drive-strength = <0x19>;
				};
			};

			ir0-0-cfg {

				ir0-0-pins {
					pinmux = <0x290005>;
					bias-pull-up;
					drive-strength = <0x19>;
				};
			};

			ir0-1-cfg {

				ir0-0-pins {
					pinmux = <0x6c0004>;
					bias-pull-up;
					drive-strength = <0x19>;
				};
			};

			ir1-0-cfg {

				ir1-0-pins {
					pinmux = <0x04>;
					bias-pull-up;
					drive-strength = <0x19>;
				};
			};

			ir1-1-cfg {

				ir1-0-pins {
					pinmux = <0x460004>;
					bias-pull-up;
					drive-strength = <0x19>;
				};
			};

			rir0-0-cfg {

				rir0-0-pins {
					pinmux = <0x280005>;
					bias-pull-up;
					drive-strength = <0x19>;
				};
			};

			rir0-1-cfg {

				rir0-0-pins {
					pinmux = <0x470004>;
					bias-pull-up;
					drive-strength = <0x19>;
				};
			};

			rir1-0-cfg {

				rir1-0-pins {
					pinmux = <0x10004>;
					bias-pull-up;
					drive-strength = <0x19>;
				};
			};

			rir1-1-cfg {

				rir1-0-pins {
					pinmux = <0x490004>;
					bias-pull-up;
					drive-strength = <0x19>;
				};
			};

			can0-0-cfg {

				can0-0-pins {
					pinmux = <0xb0003 0xc0003>;
					bias-pull-up;
					drive-strength = <0x19>;
				};
			};

			can0-1-cfg {

				can0-0-pins {
					pinmux = <0x2c0003 0x2d0003>;
					bias-pull-up;
					drive-strength = <0x19>;
				};
			};

			can0-2-cfg {

				can0-0-pins {
					pinmux = <0x4c0004 0x4d0004>;
					bias-pull-up;
					drive-strength = <0x19>;
				};
			};

			can1-0-cfg {

				can1-0-pins {
					pinmux = <0x300003 0x310003>;
					bias-pull-up;
					drive-strength = <0x19>;
				};
			};

			can1-1-cfg {

				can1-0-pins {
					pinmux = <0x580006 0x590006>;
					bias-pull-up;
					drive-strength = <0x19>;
				};
			};

			can1-2-cfg {

				can1-0-pins {
					pinmux = <0x6d0004 0x6e0004>;
					bias-pull-up;
					drive-strength = <0x19>;
				};
			};

			can2-0-cfg {

				can2-0-pins {
					pinmux = <0x320003 0x330003>;
					bias-pull-up;
					drive-strength = <0x19>;
				};
			};

			can2-1-cfg {
				phandle = <0xa0>;

				can2-0-pins {
					pinmux = <0x560004 0x570004>;
					bias-pull-up;
					drive-strength = <0x19>;
					power-source = <0xce4>;
				};
			};

			can3-0-cfg {

				can3-0-pins {
					pinmux = <0x500004 0x510004>;
					bias-pull-up;
					drive-strength = <0x19>;
				};
			};

			can3-1-cfg {

				can3-0-pins {
					pinmux = <0x670004 0x680004>;
					bias-pull-up;
					drive-strength = <0x19>;
				};
			};

			can4-0-cfg {

				can4-0-pins {
					pinmux = <0x280006 0x290006>;
					bias-pull-up;
					drive-strength = <0x19>;
				};
			};

			can4-1-cfg {

				can4-0-pins {
					pinmux = <0x650004 0x660004>;
					bias-pull-up;
					drive-strength = <0x19>;
				};
			};

			can4-2-cfg {

				can4-0-pins {
					pinmux = <0x780004 0x790004>;
					bias-pull-up;
					drive-strength = <0x19>;
				};
			};

			rcan0-0-cfg {

				rcan0-0-pins {
					pinmux = <0x390003 0x3a0003>;
					bias-pull-up;
					drive-strength = <0x19>;
				};
			};

			rcan0-1-cfg {

				rcan0-0-pins {
					pinmux = <0x5a0006 0x5b0006>;
					bias-pull-up;
					drive-strength = <0x19>;
				};
			};

			rcan1-0-cfg {

				rcan1-0-pins {
					pinmux = <0x8e0002 0x900002>;
					bias-pull-up;
					drive-strength = <0x19>;
				};
			};

			rcan2-0-cfg {

				rcan2-0-pins {
					pinmux = <0x630004 0x640004>;
					bias-pull-up;
					drive-strength = <0x19>;
				};
			};

			rcan3-0-cfg {

				rcan3-0-pins {
					pinmux = <0x780003 0x790003>;
					bias-pull-up;
					drive-strength = <0x19>;
				};
			};

			rcan4-0-cfg {

				rcan4-0-pins {
					pinmux = <0x6b0003 0x6c0003>;
					bias-pull-up;
					drive-strength = <0x19>;
				};
			};

			sspa0-0-cfg {

				sspa0-0-pins {
					pinmux = <0x510002 0x520002 0x530002 0x540002 0x550002>;
					bias-pull-up;
					drive-strength = <0x19>;
				};
			};

			sspa0-1-cfg {

				sspa0-0-pins {
					pinmux = <0x6f0002 0x700002 0x710002 0x720002 0x730002>;
					bias-pull-up;
					drive-strength = <0x19>;
				};
			};

			sspa1-0-cfg {

				sspa1-0-pins {
					pinmux = <0xf0002 0x100002 0x110002 0x120002 0x130002>;
					bias-pull-up;
					drive-strength = <0x19>;
				};
			};

			sspa1-1-cfg {

				sspa1-0-pins {
					pinmux = <0x7a0002 0x7b0002 0x7c0002 0x7d0002 0x7e0002>;
					bias-pull-up;
					drive-strength = <0x19>;
				};
			};

			sspa2-0-cfg {

				sspa2-0-pins {
					pinmux = <0x4c0002 0x4d0002 0x4e0002 0x4f0002 0x500002>;
					bias-pull-up;
					drive-strength = <0x19>;
				};
			};

			sspa3-0-cfg {

				sspa3-0-pins {
					pinmux = <0x630002 0x640002 0x650002 0x660002 0x670002>;
					bias-pull-up;
					drive-strength = <0x19>;
				};
			};

			sspa4-0-cfg {

				sspa4-0-pins {
					pinmux = <0x450002 0x460002 0x470002 0x480002 0x490002>;
					bias-pull-up;
					drive-strength = <0x19>;
				};
			};

			sspa5-0-cfg {

				sspa5-0-pins {
					pinmux = <0x02 0x10002 0x20002 0x30002 0x40002>;
					bias-pull-up;
					drive-strength = <0x19>;
				};
			};

			rsspa0-0-cfg {

				rsspa0-0-pins {
					pinmux = <0x60002 0x70002 0x80002 0x90002 0xa0002>;
					bias-pull-up;
					drive-strength = <0x19>;
				};
			};

			rsspa0-1-cfg {

				rsspa0-0-pins {
					pinmux = <0x4c0001 0x4d0001 0x4e0001 0x4f0001 0x500001>;
					bias-pull-up;
					drive-strength = <0x19>;
				};
			};

			rsspa1-0-cfg {

				rsspa1-0-pins {
					pinmux = <0x240002 0x250002 0x260002 0x270002 0x280002>;
					bias-pull-up;
					drive-strength = <0x19>;
				};
			};

			pcie0-0-cfg {

				pcie0-0-pins {
					pinmux = <0x2a0004 0x2b0004 0x2c0004>;
					bias-disable;
					drive-strength = <0x19>;
				};
			};

			pcie0-1-cfg {
				phandle = <0xd8>;

				pcie0-0-pins {
					pinmux = <0x4f0005 0x510005>;
					bias-disable;
					drive-strength = <0x26>;
					power-source = <0xce4>;
					bias-pull-up;
				};
			};

			pcie0-2-cfg {

				pcie0-0-pins {
					pinmux = <0x6c0005 0x6d0005 0x6e0005>;
					bias-disable;
					drive-strength = <0x19>;
				};
			};

			pcie1-0-cfg {

				pcie1-0-pins {
					pinmux = <0x150004 0x160004 0x170004>;
					bias-disable;
					drive-strength = <0x19>;
				};
			};

			pcie1-1-cfg {

				pcie1-0-pins {
					pinmux = <0x580004 0x590004 0x5a0004>;
					bias-disable;
					drive-strength = <0x19>;
				};
			};

			pcie1-2-cfg {

				pcie1-0-pins {
					pinmux = <0x710005 0x720005 0x730005>;
					bias-disable;
					drive-strength = <0x19>;
				};
			};

			pcie2-0-cfg {

				pcie2-0-pins {
					pinmux = <0xc0004 0xd0004 0xe0004>;
					bias-disable;
					drive-strength = <0x19>;
				};
			};

			pcie2-1-cfg {

				pcie2-0-pins {
					pinmux = <0x190004 0x1a0004 0x1b0004>;
					bias-disable;
					drive-strength = <0x19>;
				};
			};

			pcie2-2-cfg {

				pcie2-0-pins {
					pinmux = <0x3a0004 0x3b0004 0x3c0004>;
					bias-disable;
					drive-strength = <0x19>;
				};
			};

			pcie3-0-cfg {
				phandle = <0xdb>;

				pcie3-0-pins {
					pinmux = <0x30004 0x50004>;
					bias-disable;
					drive-strength = <0x26>;
					bias-pull-up;
					power-source = <0xce4>;
				};
			};

			pcie3-1-cfg {

				pcie3-0-pins {
					pinmux = <0x690005 0x6a0005 0x6b0005>;
					bias-disable;
					drive-strength = <0x19>;
				};
			};

			pcie3-2-cfg {

				pcie3-0-pins {
					pinmux = <0x7c0003 0x7d0003 0x7e0003>;
					bias-disable;
					drive-strength = <0x19>;
				};
			};

			pcie4-0-cfg {

				pcie4-0-pins {
					pinmux = <0x1f0004 0x200004 0x210004>;
					bias-disable;
					drive-strength = <0x19>;
				};
			};

			pcie4-1-cfg {
				phandle = <0xdd>;

				pcie4-0-pins {
					pinmux = <0x4c0005 0x500005 0x4e0005>;
					bias-disable;
					drive-strength = <0x26>;
					bias-pull-up;
					power-source = <0xce4>;
				};
			};

			gmac0-cfg {

				gmac0-0-pins {
					pinmux = <0x01 0x10001 0x20001 0x30001 0x60001 0x70001 0xb0001 0xc0001 0xd0001>;
					bias-disable;
					drive-strength = <0x19>;
				};

				gmac0-1-pins {
					pinmux = <0x40001 0x50001 0x80001 0x90001 0xa0001>;
					bias-disable;
					drive-strength = <0x19>;
				};

				gmac0-2-pins {
					pinmux = <0xf0001 0x100001 0x110001 0x120001>;
					bias-disable;
					drive-strength = <0x19>;
				};

				gmac0-3-pins {
					pinmux = <0xe0001>;
					bias-disable;
					drive-strength = <0x19>;
				};

				gmac0-4-pins {
					pinmux = <0x130001>;
					bias-disable;
					drive-strength = <0x19>;
				};

				gmac0-5-pins {
					pinmux = <0x140001>;
					bias-disable;
					drive-strength = <0x19>;
				};
			};

			gmac1-cfg {
				phandle = <0xce>;

				gmac1-0-pins {
					pinmux = <0x150001 0x160001 0x170001 0x180001 0x1b0001 0x1c0001 0x200001 0x210001 0x220001>;
					bias-disable;
					drive-strength = <0x19>;
					power-source = <0x708>;
				};

				gmac1-1-pins {
					pinmux = <0x190001 0x1a0001 0x1d0001 0x1e0001 0x1f0001>;
					bias-disable;
					drive-strength = <0x19>;
					power-source = <0x708>;
				};

				gmac1-3-pins {
					pinmux = <0x230001>;
					bias-disable;
					drive-strength = <0x19>;
					power-source = <0x708>;
				};

				gmac1-6-pins {
					pinmux = <0x250000>;
					bias-disable;
					drive-strength = <0x19>;
					power-source = <0x708>;
				};
			};

			gmac2-cfg {

				gmac2-0-pins {
					pinmux = <0x2a0001 0x2b0001 0x2c0001 0x2d0001 0x300001 0x310001 0x350001 0x360001 0x370001>;
					bias-disable;
					drive-strength = <0x19>;
				};

				gmac2-1-pins {
					pinmux = <0x2e0001 0x2f0001 0x320001 0x330001 0x340001>;
					bias-disable;
					drive-strength = <0x19>;
				};

				gmac2-2-pins {
					pinmux = <0x380001>;
					bias-disable;
					drive-strength = <0x19>;
				};

				gmac2-3-pins {
					pinmux = <0x3a0001>;
					bias-disable;
					drive-strength = <0x19>;
				};

				gmac2-4-pins {
					pinmux = <0x390001>;
					bias-disable;
					drive-strength = <0x19>;
				};
			};

			gmac3-cfg {

				gmac3-0-pins {
					pinmux = <0x3b0001 0x3c0001 0x3d0001 0x3e0001 0x410001 0x420001 0x460001 0x470001 0x480001>;
					bias-disable;
					drive-strength = <0x19>;
				};

				gmac3-1-pins {
					pinmux = <0x3f0001 0x400001 0x430001 0x440001 0x450001>;
					bias-disable;
					drive-strength = <0x19>;
				};

				gmac3-2-pins {
					pinmux = <0x490001>;
					bias-disable;
					drive-strength = <0x19>;
				};

				gmac3-3-pins {
					pinmux = <0x4b0001>;
					bias-disable;
					drive-strength = <0x19>;
				};

				gmac3-4-pins {
					pinmux = <0x4a0001>;
					bias-disable;
					drive-strength = <0x19>;
				};
			};

			ssp0-0-cfg {

				ssp0-0-pins {
					pinmux = <0x350003 0x360003 0x370003>;
					bias-disable;
					drive-strength = <0x19>;
				};

				ssp0-1-pins {
					pinmux = <0x380003>;
					bias-pull-up;
					drive-strength = <0x19>;
				};
			};

			ssp0-1-cfg {

				ssp0-0-pins {
					pinmux = <0x510001 0x520001 0x530001>;
					bias-disable;
					drive-strength = <0x19>;
				};

				ssp0-1-pins {
					pinmux = <0x540001>;
					bias-pull-up;
					drive-strength = <0x19>;
				};
			};

			ssp0-2-cfg {

				ssp0-0-pins {
					pinmux = <0x680001 0x690001 0x6a0001>;
					bias-disable;
					drive-strength = <0x19>;
				};

				ssp0-1-pins {
					pinmux = <0x6b0001>;
					bias-pull-up;
					drive-strength = <0x19>;
				};
			};

			ssp1-0-cfg {

				ssp1-0-pins {
					pinmux = <0x200005 0x210005 0x220005>;
					bias-disable;
					drive-strength = <0x19>;
				};

				ssp1-1-pins {
					pinmux = <0x230005>;
					bias-pull-up;
					drive-strength = <0x19>;
				};
			};

			ssp1-1-cfg {

				ssp1-0-pins {
					pinmux = <0x6f0001 0x700001 0x710001>;
					bias-disable;
					drive-strength = <0x19>;
				};

				ssp1-1-pins {
					pinmux = <0x720001>;
					bias-pull-up;
					drive-strength = <0x19>;
				};
			};

			ssp2-0-cfg {

				ssp2-0-pins {
					pinmux = <0x1c0005 0x1d0005 0x1e0005>;
					bias-disable;
					drive-strength = <0x19>;
				};

				ssp2-1-pins {
					pinmux = <0x1f0005>;
					bias-pull-up;
					drive-strength = <0x19>;
				};
			};

			ssp2-1-cfg {

				ssp2-0-pins {
					pinmux = <0x680002 0x690002 0x6a0002>;
					bias-disable;
					drive-strength = <0x19>;
				};

				ssp2-1-pins {
					pinmux = <0x6b0002>;
					bias-pull-up;
					drive-strength = <0x19>;
				};
			};

			ssp3-0-cfg {

				ssp3-0-pins {
					pinmux = <0x440006 0x450006 0x460006>;
					bias-disable;
					drive-strength = <0x19>;
				};

				ssp3-1-pins {
					pinmux = <0x470006>;
					bias-pull-up;
					drive-strength = <0x19>;
				};
			};

			ssp3-1-cfg {

				ssp3-0-pins {
					pinmux = <0x630001 0x640001 0x650001>;
					bias-disable;
					drive-strength = <0x19>;
				};

				ssp3-1-pins {
					pinmux = <0x660001>;
					bias-pull-up;
					drive-strength = <0x19>;
				};
			};

			rssp0-0-cfg {

				rssp0-0-pins {
					pinmux = <0x3c0003 0x3d0003 0x3e0003>;
					bias-disable;
					drive-strength = <0x19>;
				};

				rssp0-1-pins {
					pinmux = <0x3f0003>;
					bias-pull-up;
					drive-strength = <0x19>;
				};
			};

			rssp0-1-cfg {

				rssp0-0-pins {
					pinmux = <0x560001 0x570001 0x580001>;
					bias-disable;
					drive-strength = <0x19>;
				};

				rssp0-1-pins {
					pinmux = <0x590001>;
					bias-pull-up;
					drive-strength = <0x19>;
				};
			};

			rssp1-0-cfg {

				rssp1-0-pins {
					pinmux = <0x400003 0x410003 0x420003>;
					bias-disable;
					drive-strength = <0x19>;
				};

				rssp1-1-pins {
					pinmux = <0x430003>;
					bias-pull-up;
					drive-strength = <0x19>;
				};
			};

			rssp1-1-cfg {

				rssp1-0-pins {
					pinmux = <0x6c0001 0x6d0001 0x740001>;
					bias-disable;
					drive-strength = <0x19>;
				};

				rssp1-1-pins {
					pinmux = <0x750001>;
					bias-pull-up;
					drive-strength = <0x19>;
				};
			};

			pwr_ssp-cfg {

				pwr_ssp-0-pins {
					pinmux = <0x970000 0x980000 0x950000>;
					bias-disable;
					drive-strength = <0x19>;
				};

				pwr_ssp-1-pins {
					pinmux = <0x960000>;
					bias-pull-up;
					drive-strength = <0x19>;
				};
			};

			qspi-cfg {
				phandle = <0x98>;

				qspi-0-pins {
					pinmux = <0x8a0000 0x8b0000 0x8c0000 0x8d0000 0x900000>;
					bias-disable;
					drive-strength = <0x19>;
					power-source = <0x708>;
				};
			};

			espi0-0-cfg {

				espi0-0-pins {
					pinmux = <0x05 0x10005 0x20005 0x30005 0x40005 0x60005 0x70005>;
					bias-pull-up;
					drive-strength = <0x19>;
				};

				espi0-1-pins {
					pinmux = <0x50005>;
					bias-pull-down;
					drive-strength = <0x19>;
				};
			};

			espi0-1-cfg {

				espi0-0-pins {
					pinmux = <0x440003 0x450003 0x460003 0x470003 0x480003 0x4a0003 0x4b0003>;
					bias-pull-up;
					drive-strength = <0x19>;
				};

				espi0-1-pins {
					pinmux = <0x490003>;
					bias-pull-down;
					drive-strength = <0x19>;
				};
			};

			espi0-2-cfg {

				espi0-0-pins {
					pinmux = <0x5b0004 0x5c0004 0x5d0004 0x5e0004 0x5f0004 0x610004 0x620004>;
					bias-pull-up;
					drive-strength = <0x19>;
					power-source = <0x708>;
				};

				espi0-1-pins {
					pinmux = <0x600004>;
					bias-pull-down;
					drive-strength = <0x19>;
					power-source = <0x708>;
				};
			};

			respi0-cfg {

				respi0-0-pins {
					pinmux = <0x560002 0x570002 0x580002 0x590002 0x5a0002 0x5c0002 0x5d0002>;
					bias-pull-up;
					drive-strength = <0x19>;
				};

				respi0-1-pins {
					pinmux = <0x5b0002>;
					bias-pull-down;
					drive-strength = <0x19>;
				};
			};

			mmc1-cfg {
				phandle = <0xd1>;

				mmc1-0-pins {
					pinmux = <0x840000 0x850000 0x860000 0x870000 0x880000>;
					bias-pull-up;
					drive-strength = <0x08>;
					power-source = <0xce4>;
				};

				mmc1-1-pins {
					pinmux = <0x890000>;
					bias-pull-down;
					drive-strength = <0x08>;
					power-source = <0xce4>;
				};
			};

			mmc1-uhs-cfg {
				phandle = <0xd3>;

				mmc1-0-pins {
					pinmux = <0x840000 0x850000 0x860000 0x870000 0x880000>;
					bias-pull-up;
					drive-strength = <0x07>;
					power-source = <0x708>;
				};

				mmc1-1-pins {
					pinmux = <0x890000>;
					bias-pull-down;
					drive-strength = <0x06>;
					power-source = <0x708>;
				};
			};

			mmc1-debug-cfg {

				mmc1-0-pins {
					pinmux = <0x840002 0x850002 0x860000 0x870000 0x880000>;
					bias-pull-up;
					drive-strength = <0x08>;
					power-source = <0xce4>;
				};

				mmc1-1-pins {
					pinmux = <0x890000>;
					bias-pull-down;
					drive-strength = <0x08>;
					power-source = <0xce4>;
				};
			};

			mmc2-cfg {

				mmc2-0-pins {
					pinmux = <0x7a0001 0x7b0001 0x7c0001 0x7d0001 0x7e0001>;
					bias-pull-up;
					drive-strength = <0x19>;
				};

				mmc2-1-pins {
					pinmux = <0x7f0001>;
					bias-pull-down;
					drive-strength = <0x19>;
				};
			};

			cam0-0-cfg {

				cam0-0-pins {
					pinmux = <0xd0005>;
					bias-disable;
					drive-strength = <0x19>;
				};
			};

			cam0-1-cfg {

				cam0-0-pins {
					pinmux = <0x2e0003>;
					bias-disable;
					drive-strength = <0x19>;
				};
			};

			cam0-2-cfg {
				phandle = <0x95>;

				cam1-0-pins {
					pinmux = <0x4b0002>;
					bias-disable;
					drive-strength = <0x19>;
					power-source = <0x708>;
				};
			};

			cam1-0-cfg {

				cam1-0-pins {
					pinmux = <0x220004>;
					bias-disable;
					drive-strength = <0x19>;
				};
			};

			cam1-1-cfg {

				cam1-0-pins {
					pinmux = <0x2f0003>;
					bias-disable;
					drive-strength = <0x19>;
				};
			};

			cam1-2-cfg {

				cam0-0-pins {
					pinmux = <0x4a0002>;
					bias-disable;
					drive-strength = <0x19>;
				};
			};

			cam2-0-cfg {

				cam2-0-pins {
					pinmux = <0x230004>;
					bias-disable;
					drive-strength = <0x19>;
				};
			};

			cam2-1-cfg {

				cam2-0-pins {
					pinmux = <0x340005>;
					bias-disable;
					drive-strength = <0x19>;
				};
			};

			cam2-2-cfg {

				cam2-0-pins {
					pinmux = <0x550001>;
					bias-disable;
					drive-strength = <0x19>;
				};
			};

			cam3-0-cfg {

				cam3-0-pins {
					pinmux = <0x2b0003>;
					bias-disable;
					drive-strength = <0x19>;
				};
			};

			cam3-1-cfg {

				cam3-0-pins {
					pinmux = <0x430004>;
					bias-disable;
					drive-strength = <0x19>;
				};
			};

			cam3-2-cfg {

				cam3-0-pins {
					pinmux = <0x630006>;
					bias-disable;
					drive-strength = <0x19>;
				};
			};

			dsi-0-cfg {

				dsi-0-pins {
					pinmux = <0xd0006>;
					bias-disable;
					drive-strength = <0x19>;
				};
			};

			dsi-1-cfg {

				dsi-0-pins {
					pinmux = <0x260006>;
					bias-disable;
					drive-strength = <0x19>;
				};
			};

			dsi-2-cfg {

				dsi-0-pins {
					pinmux = <0x450005>;
					bias-disable;
					drive-strength = <0x19>;
				};
			};

			dsi-3-cfg {

				dsi-0-pins {
					pinmux = <0x480005>;
					bias-disable;
					drive-strength = <0x19>;
				};
			};

			dsi-4-cfg {

				dsi-0-pins {
					pinmux = <0x540006>;
					bias-disable;
					drive-strength = <0x19>;
				};
			};

			dsi-5-cfg {

				dsi-0-pins {
					pinmux = <0x5a0001>;
					bias-disable;
					drive-strength = <0x19>;
				};
			};

			dsi-6-cfg {

				dsi-0-pins {
					pinmux = <0x5c0006>;
					bias-disable;
					drive-strength = <0x19>;
				};
			};

			edp0-0-cfg {

				edp0-0-pins {
					pinmux = <0x1e0006>;
					bias-disable;
					drive-strength = <0x19>;
				};
			};

			edp0-1-cfg {

				edp0-0-pins {
					pinmux = <0x390004>;
					bias-disable;
					drive-strength = <0x19>;
				};
			};

			edp1-0-cfg {

				edp1-0-pins {
					pinmux = <0x1f0006>;
					bias-disable;
					drive-strength = <0x19>;
				};
			};

			dp0-0-cfg {

				dp0-0-pins {
					pinmux = <0x90006>;
					bias-disable;
					drive-strength = <0x19>;
				};
			};

			dp0-1-cfg {

				dp0-0-pins {
					pinmux = <0x170006>;
					bias-disable;
					drive-strength = <0x19>;
				};
			};

			dp0-2-cfg {

				dp0-0-pins {
					pinmux = <0x610005>;
					bias-disable;
					drive-strength = <0x19>;
					power-source = <0xce4>;
				};
			};

			dp0-3-cfg {

				dp0-0-pins {
					pinmux = <0x7c0004>;
					bias-disable;
					drive-strength = <0x19>;
				};
			};

			dp1-0-cfg {

				dp1-0-pins {
					pinmux = <0xa0006>;
					bias-disable;
					drive-strength = <0x19>;
				};
			};

			dp1-1-cfg {

				dp1-0-pins {
					pinmux = <0x180006>;
					bias-disable;
					drive-strength = <0x19>;
				};
			};

			dp1-2-cfg {

				dp1-0-pins {
					pinmux = <0x450004>;
					bias-disable;
					drive-strength = <0x19>;
				};
			};

			dp1-3-cfg {
				phandle = <0xff>;

				dp1-0-pins {
					pinmux = <0x480004>;
					bias-disable;
					drive-strength = <0x19>;
					power-source = <0xce4>;
				};
			};

			dp1-4-cfg {

				dp1-0-pins {
					pinmux = <0x620005>;
					bias-disable;
					drive-strength = <0x19>;
					power-source = <0xce4>;
				};
			};

			dp1-5-cfg {

				dp1-0-pins {
					pinmux = <0x7d0004>;
					bias-disable;
					drive-strength = <0x19>;
				};
			};

			usb20_host_drv-0-cfg {

				usb20_host_drv-pins {
					pinmux = <0x100006>;
					bias-disable;
					drive-strength = <0x19>;
				};
			};

			usb20_host_drv-1-cfg {

				usb20_host_drv-pins {
					pinmux = <0x270005>;
					bias-disable;
					drive-strength = <0x19>;
				};
			};

			usb20_host_drv-2-cfg {

				usb20_host_drv-pins {
					pinmux = <0x490005>;
					bias-disable;
					drive-strength = <0x19>;
				};
			};

			usb20_host_drv-3-cfg {

				usb20_host_drv-pins {
					pinmux = <0x670003>;
					bias-disable;
					drive-strength = <0x19>;
				};
			};

			usb20_host_drv-4-cfg {

				usb20_host_drv-pins {
					pinmux = <0x6c0002>;
					bias-disable;
					drive-strength = <0x19>;
				};
			};

			usb30_drd-0-cfg {

				usb30_drd-pins {
					pinmux = <0x110006 0x120006 0x130006>;
					bias-pull-down;
					drive-strength = <0x19>;
				};
			};

			usb30_drd-1-cfg {

				usb30_drd-pins {
					pinmux = <0x5f0003 0x600003 0x610003>;
					bias-pull-down;
					drive-strength = <0x19>;
				};
			};

			usb30_drd-2-cfg {

				usb30_drd-pins {
					pinmux = <0x740002 0x750002 0x760002>;
					bias-pull-down;
					drive-strength = <0x19>;
				};
			};

			usb30_drd_int-0-cfg {

				usb30_drd_int-pins {
					pinmux = <0x6f0005>;
					bias-pull-down;
					drive-strength = <0x19>;
				};
			};

			usb30_drd_int-1-cfg {

				usb30_drd_int-pins {
					pinmux = <0x770002>;
					bias-pull-down;
					drive-strength = <0x19>;
				};
			};

			usb30_b_drv-0-cfg {

				usb30_c_drv-pins {
					pinmux = <0x540004>;
					bias-pull-down;
					drive-strength = <0x19>;
				};
			};

			usb30_c_drv-0-cfg {

				usb30_c_drv-pins {
					pinmux = <0x550004>;
					bias-pull-down;
					drive-strength = <0x19>;
				};
			};

			usb30_c_drv-1-cfg {

				usb30_c_drv-pins {
					pinmux = <0x7f0006>;
					bias-pull-down;
					drive-strength = <0x19>;
				};
			};

			usb30_d_drv-0-cfg {

				usb30_d_drv-pins {
					pinmux = <0x140006>;
					bias-pull-down;
					drive-strength = <0x19>;
				};
			};

			usb30_d_drv-1-cfg {

				usb30_d_drv-pins {
					pinmux = <0x1b0005>;
					bias-pull-down;
					drive-strength = <0x19>;
				};
			};

			usb30_d_drv-2-cfg {

				usb30_d_drv-pins {
					pinmux = <0x700005>;
					bias-pull-down;
					drive-strength = <0x19>;
				};
			};

			usb30h1_drv-0-cfg {

				usb30h1_drv-pins {
					pinmux = <0x4a0005>;
					bias-pull-down;
					drive-strength = <0x19>;
				};
			};

			usb30h1_drv-1-cfg {

				usb30h1_drv-pins {
					pinmux = <0x680003>;
					bias-pull-down;
					drive-strength = <0x19>;
				};
			};

			usb30h2_drv-0-cfg {

				usb30h2_drv-pins {
					pinmux = <0x4b0005>;
					bias-pull-down;
					drive-strength = <0x19>;
				};
			};

			usb30_drd_dir-0-cfg {

				usb30_drd_dir-pins {
					pinmux = <0x560006>;
					bias-pull-down;
					drive-strength = <0x19>;
				};
			};

			usb30_drd_dir-1-cfg {

				usb30_drd_dir-pins {
					pinmux = <0x6b0004>;
					bias-pull-down;
					drive-strength = <0x19>;
				};
			};

			fusb301-cfg {
				phandle = <0x8a>;

				fusb301-0-pins {
					pinmux = <0x3a0000>;
					bias-pull-up;
					drive-strength = <0x19>;
					power-source = <0x708>;
				};
			};

			m2-wdis1-cfg {
				phandle = <0x101>;

				m2-wdis1-pins {
					pinmux = <0x490000>;
					bias-pull-up;
					drive-strength = <0x26>;
					power-source = <0xce4>;
				};
			};

			m2-wdis2-cfg {
				phandle = <0x102>;

				m2-wdis2-pins {
					pinmux = <0x390000>;
					bias-pull-up;
					drive-strength = <0x26>;
					power-source = <0xce4>;
				};
			};

			cam-mux-cfg {
				phandle = <0x94>;

				cam-mux-pins {
					pinmux = <0x670000>;
					bias-pull-up;
					drive-strength = <0x19>;
					power-source = <0x708>;
				};
			};

			mmc1-cd-cfg {
				phandle = <0xd2>;

				mmc1-cd-pins {
					pinmux = <0x40000>;
					bias-pull-up = <0x01>;
					drive-strength = <0x08>;
					power-source = <0xce4>;
				};
			};
		};

		serial@d4017000 {
			compatible = "spacemit,k1-uart\0intel,xscale-uart";
			reg = <0x00 0xd4017000 0x00 0x100>;
			clocks = <0x81 0x00 0x81 0x0a 0x80 0x19>;
			clock-names = "core\0bus\0gate";
			resets = <0x81 0x00>;
			reg-shift = <0x02>;
			reg-io-width = <0x04>;
			fifo-size = <0x100>;
			tx-threshold = <0x20>;
			interrupt-parent = <0x82>;
			interrupts = <0x2a 0x04>;
			status = "okay";
			pinctrl-names = "default";
			pinctrl-0 = <0x86>;
		};

		ufshc@0xc0e00000 {
			#address-cells = <0x02>;
			#size-cells = <0x02>;
			compatible = "spacemit,k3-ufshcd";
			reg = <0x00 0xc0e00000 0x00 0x40000>;
			interrupt-parent = <0x82>;
			interrupts = <0x87 0x04>;
			clocks = <0x05 0x37>;
			clock-names = "ufs-aclk";
			resets = <0x05 0x3b>;
			reset-names = "ufs-aclk-rst";
			clock-freq = <0x1d4c0000>;
			freq-table-hz = <0x1d4c0000 0x1d4c0000>;
			lanes-per-direction = <0x02>;
			ref-clk-freq = <0x124f800>;
		};

		stmmac-axi-config {
			snps,wr_osr_lmt = <0x0f>;
			snps,rd_osr_lmt = <0x0f>;
			snps,blen = <0x100 0x80 0x40 0x20 0x10 0x00 0x00>;
			phandle = <0xcb>;
		};

		ethernet@cac82000 {
			compatible = "spacemit,k3-gmac\0snps,dwmac-5.10a";
			reg = <0x00 0xcac82000 0x00 0x2000>;
			spacemit,apmu = <0x05>;
			spacemit,ctrl-offset = <0x3ec>;
			spacemit,dline-offset = <0x3f0>;
			clocks = <0x05 0x4e 0x05 0x50>;
			clock-names = "stmmaceth\0ptp_ref";
			resets = <0x05 0x4e>;
			reset-names = "stmmaceth";
			interrupt-parent = <0x82>;
			interrupts = <0x85 0x04 0x115 0x04>;
			interrupt-names = "macirq\0eth_wake_irq";
			mac-address = [00 00 00 00 00 00];
			tx-fifo-depth = <0x2000>;
			rx-fifo-depth = <0x2000>;
			snps,tso;
			snps,force_sf_dma_mode;
			snps,axi-config = <0xcb>;
			snps,mtl-rx-config = <0xcc>;
			snps,mtl-tx-config = <0xcd>;
			status = "okay";
			pinctrl-names = "default";
			pinctrl-0 = <0xce>;
			max-speed = <0x3e8>;
			phy-mode = "rgmii";
			phy-handle = <0xcf>;
			snps,reset-gpios = <0x8b 0x01 0x05 0x01>;
			snps,reset-delays-us = <0x00 0x4e20 0x186a0>;
			spacemit,wake-irq-enable;
			spacemit,clk-tuning-enable;
			spacemit,clk-tuning-by-delayline;
			spacemit,tx-phase = <0x2f>;
			spacemit,rx-phase = <0x35>;
			phandle = <0xca>;

			mdio {
				#address-cells = <0x01>;
				#size-cells = <0x00>;
				compatible = "snps,dwmac-mdio";

				ethernet-phy@1 {
					compatible = "ethernet-phy-id001c.c916\0ethernet-phy-ieee802.3-c22";
					reg = <0x01>;
					phandle = <0xcf>;

					leds {
						#address-cells = <0x01>;
						#size-cells = <0x00>;

						led@1 {
							reg = <0x01>;
							function = "lan";
							color = <0x02>;
							default-state = "keep";
						};

						led@2 {
							reg = <0x02>;
							function = "lan";
							color = <0x06>;
							default-state = "keep";
						};
					};
				};
			};
		};
		
		mpxy_mbox@0 {
			compatible = "riscv,sbi-mpxy-mbox";
			#mbox-cells = <0x02>;
			status = "okay";
			phandle = <0xa8>;
		};

		rpmi_regulator@0 {
			compatible = "riscv,rpmi-regulator";
			mboxes = <0xa8 0x07 0x00>;
			status = "okay";
			pinctrl-names = "default";
			pinctrl-0 = <0xa9>;

			pvin {
				regulator-min-microvolt = <0x4c4b40>;
				regulator-max-microvolt = <0x4c4b40>;
				regulator-always-on;
				regulator-boot-on;
			};

			edcdc2 {
				regulator-min-microvolt = <0x825f0>;
				regulator-max-microvolt = <0xf55c8>;
				regulator-always-on;
				regulator-boot-on;
			};

			edcdc1 {
				regulator-min-microvolt = <0x825f0>;
				regulator-max-microvolt = <0xf55c8>;
				regulator-always-on;
				regulator-boot-on;
				phandle = <0x04>;
			};

			p3v3 {
				regulator-min-microvolt = <0x325aa0>;
				regulator-max-microvolt = <0x325aa0>;
				regulator-always-on;
				regulator-boot-on;
				phandle = <0xd4>;
			};

			p1v8 {
				regulator-min-microvolt = <0x1b7740>;
				regulator-max-microvolt = <0x1b7740>;
				regulator-always-on;
				regulator-boot-on;
			};

			dcdc1 {
				regulator-min-microvolt = <0x100590>;
				regulator-max-microvolt = <0x100590>;
				regulator-always-on;
				regulator-boot-on;
			};

			dcdc3 {
				regulator-min-microvolt = "\0\f5";
				regulator-max-microvolt = "\0\f5";
				regulator-always-on;
				regulator-boot-on;
			};

			dcdc4 {
				regulator-min-microvolt = <0x200b20>;
				regulator-max-microvolt = <0x200b20>;
				regulator-always-on;
				regulator-boot-on;
			};

			dcdc5 {
				regulator-min-microvolt = <0x1b7740>;
				regulator-max-microvolt = <0x1b7740>;
				regulator-always-on;
				regulator-boot-on;
			};

			dcdc6 {
				regulator-min-microvolt = <0x7a120>;
				regulator-max-microvolt = <0x927c0>;
				regulator-always-on;
				regulator-boot-on;
			};

			aldo1 {
				regulator-min-microvolt = <0x1b7740>;
				regulator-max-microvolt = <0x325aa0>;
				regulator-always-on;
				regulator-boot-on;
				phandle = <0xd5>;
			};

			aldo2 {
				regulator-min-microvolt = <0x1b7740>;
				regulator-max-microvolt = <0x1b7740>;
				regulator-always-on;
				regulator-boot-on;
			};

			aldo3 {
				regulator-min-microvolt = <0x7a120>;
				regulator-max-microvolt = <0x33e140>;
				phandle = <0x93>;
			};

			aldo4 {
				regulator-min-microvolt = <0x325aa0>;
				regulator-max-microvolt = <0x325aa0>;
				regulator-always-on;
				regulator-boot-on;
			};

			dldo1 {
				regulator-min-microvolt = <0x124f80>;
				regulator-max-microvolt = <0x124f80>;
				regulator-always-on;
				regulator-boot-on;
			};

			dldo2 {
				regulator-min-microvolt = <0xdbba0>;
				regulator-max-microvolt = <0xdbba0>;
				regulator-always-on;
				regulator-boot-on;
			};

			dldo3 {
				regulator-min-microvolt = "\0\f5";
				regulator-max-microvolt = "\0\f5";
				regulator-always-on;
				regulator-boot-on;
			};

			dldo4 {
				regulator-min-microvolt = <0x1b7740>;
				regulator-max-microvolt = <0x1b7740>;
				regulator-always-on;
				regulator-boot-on;
			};

			dldo5 {
				regulator-min-microvolt = <0x1b7740>;
				regulator-max-microvolt = <0x1b7740>;
				regulator-always-on;
				regulator-boot-on;
			};

			dldo6 {
				regulator-min-microvolt = <0x1b7740>;
				regulator-max-microvolt = <0x1b7740>;
				regulator-always-on;
				regulator-boot-on;
			};

			dldo7 {
				regulator-min-microvolt = <0x1b7740>;
				regulator-max-microvolt = <0x1b7740>;
				regulator-always-on;
				regulator-boot-on;
			};

			pwr_x100 {
				regulator-min-microvolt = <0x325aa0>;
				regulator-max-microvolt = <0x325aa0>;
				regulator-always-on;
				regulator-boot-on;
			};

			pwr_a100 {
				regulator-min-microvolt = <0x325aa0>;
				regulator-max-microvolt = <0x325aa0>;
				regulator-always-on;
				regulator-boot-on;
			};

			pwr_ext {
				regulator-min-microvolt = <0x325aa0>;
				regulator-max-microvolt = <0x325aa0>;
				regulator-always-on;
				regulator-boot-on;
			};
		};

		mmc@d4280000 {
			compatible = "spacemit,k3-sdhci";
			reg = <0x00 0xd4280000 0x00 0x200>;
			clocks = <0x05 0x1c 0x05 0x1d>;
			clock-names = "core\0io";
			interrupt-parent = <0x82>;
			interrupts = <0x63 0x04>;
			resets = <0x05 0x0c 0x05 0x0d>;
			reset-names = "sdh_axi\0sdh0";
			status = "okay";
			pinctrl-names = "default\0uhs";
			pinctrl-0 = <0xd1 0xd2>;
			pinctrl-1 = <0xd3 0xd2>;
			bus-width = <0x04>;
			wp-inverted;
			cd-gpios = <0x8b 0x00 0x04 0x00>;
			vmmc-supply = <0xd4>;
			vqmmc-supply = <0xd5>;
			no-mmc;
			no-sdio;
			clock-frequency = "\f5\0";
			spacemit,tx_delaycode = <0x1f>;
		};
	};

	aliases {
		serial0 = "/soc/serial@d4017000";
	};

	clocks {
		clock-1m {
			compatible = "fixed-clock";
			clock-frequency = <0xf4240>;
			clock-output-names = "vctcxo_1m";
			#clock-cells = <0x00>;
			phandle = <0x7b>;
		};

		clock-24m {
			compatible = "fixed-clock";
			clock-frequency = <0x16e3600>;
			clock-output-names = "vctcxo_24m";
			#clock-cells = <0x00>;
			phandle = <0x7d>;
		};

		clock-3m {
			compatible = "fixed-clock";
			clock-frequency = <0x2dc6c0>;
			clock-output-names = "vctcxo_3m";
			#clock-cells = <0x00>;
			phandle = <0x7c>;
		};

		clock-32k {
			compatible = "fixed-clock";
			clock-frequency = <0x8000>;
			clock-output-names = "osc_32k";
			#clock-cells = <0x00>;
			phandle = <0x7a>;
		};

		clock-reserved {
			compatible = "fixed-clock";
			clock-frequency = <0x00>;
			clock-output-names = "reserved_clk";
			#clock-cells = <0x00>;
			phandle = <0x7e>;
		};

		clock-external {
			compatible = "fixed-clock";
			clock-frequency = <0x00>;
			clock-output-names = "external_clk";
			#clock-cells = <0x00>;
			phandle = <0x7f>;
		};
	};

	memory@107000000 {
		device_type = "memory";
		reg = <0x01 0x07000000 0x0 0xF9000000>;
	};

	apb-pclk {
		compatible = "fixed-clock";
		#clock-cells = <0x00>;
		clock-output-names = "clk14mhz";
		clock-frequency = <0xd59f80>;
		phandle = <0x60>;
	};

	reserved-memory {
		#address-cells = <0x02>;
		#size-cells = <0x02>;
		ranges;

		nonroot@180000000 {
			no-map;
			reg = <0x01 0x80000000 0x00 0x80000000>;
		};

		dtbfile@10f000000 {
			no-map;
			reg = <0x01 0x0f000000 0x00 0x01000000>;
		};

		rcpu0_pwr@100200000 {
			reg = <0x01 0x200000 0x00 0x300000>;
			no-map;
			phandle = <0x9a>;
		};

		rcpu0_heap@100500000 {
			reg = <0x01 0x500000 0x00 0x200000>;
			no-map;
			phandle = <0x9b>;
		};

		vdev0vring0@c0876000 {
			reg = <0x00 0xc0876000 0x00 0x3000>;
			no-map;
			phandle = <0x9c>;
		};

		vdev0vring1@c0879000 {
			reg = <0x00 0xc0879000 0x00 0x3000>;
			no-map;
			phandle = <0x9e>;
		};

		vdev0vring2@c087c000 {
			reg = <0x00 0xc087c000 0x00 0x1000>;
			no-map;
		};

		vdev0buffer@100700000 {
			compatible = "shared-dma-pool";
			reg = <0x01 0x700000 0x00 0xfc000>;
			no-map;
			phandle = <0x9d>;
		};

		rcpu0_rsc_table@1007fc000 {
			reg = <0x01 0x7fc000 0x00 0x4000>;
			no-map;
			phandle = <0x9f>;
		};

		rpmi0@100800000 {
			reg = <0x01 0x800000 0x00 0x4000>;
			no-map;
		};

		rcpu1_runtime@100804000 {
			reg = <0x01 0x804000 0x00 0x300000>;
			no-map;
			phandle = <0xa2>;
		};

		rcpu1_heap@100B04000 {
			reg = <0x01 0xb04000 0x00 0x200000>;
			no-map;
			phandle = <0xa3>;
		};

		vdev0vring0@c086c000 {
			reg = <0x00 0xc086c000 0x00 0x3000>;
			no-map;
			phandle = <0xa4>;
		};

		vdev0vring1@c086f000 {
			reg = <0x00 0xc086f000 0x00 0x3000>;
			no-map;
			phandle = <0xa6>;
		};

		vdev0buffer@100d04000 {
			compatible = "shared-dma-pool";
			reg = <0x01 0xd04000 0x00 0xfc000>;
			no-map;
			phandle = <0xa5>;
		};

		rcpu1_rsc_table@100e00000 {
			reg = <0x01 0xe00000 0x00 0x4000>;
			no-map;
			phandle = <0xa7>;
		};

		rcpu_dtb_table@100e04000 {
			reg = <0x01 0xe04000 0x00 0x300000>;
			no-map;
		};

		dpu_reserved@101b00000 {
			compatible = "shared-dma-pool";
			reg = <0x01 0x1b00000 0x00 0x280000>;
			no-map;
			phandle = <0xf2>;
		};

		dpu_reserved1@101d80000 {
			compatible = "shared-dma-pool";
			reg = <0x01 0x1d80000 0x00 0x280000>;
			no-map;
			phandle = <0xf5>;
		};

		linux,cma {
			compatible = "shared-dma-pool";
			reusable;
			size = <0x00 0x20000000>;
			alloc-ranges = <0x01 0x40000000 0x00 0x20000000>;
			linux,cma-default;
		};
	};

	hvisor_virtio_device {
		compatible = "hvisor";
		interrupt-parent = <0x82>;
		interrupts = <0x20 0x04>;
	};

	chosen {
		bootargs = "earlycon=sbi console=ttyS0,115200 loglevel=8 root=/dev/sda3 rootwait rw random.trust_bootloader=1 unaligned_scalar_speed=fast unaligned_vector_speed=fast";
		stdout-path = "serial0:115200";
	};

	hub-reset {
		compatible = "regulator-fixed";
		regulator-name = "hub-reset";
		regulator-min-microvolt = <0x325aa0>;
		regulator-max-microvolt = <0x325aa0>;
		enable-active-high;
		regulator-boot-on;
		gpio = <0x8b 0x01 0x15 0x00>;
		phandle = <0xc3>;
	};
};
